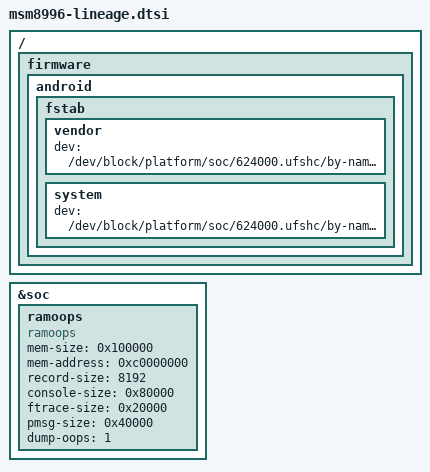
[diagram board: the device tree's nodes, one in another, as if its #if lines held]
/* Copyright (c) 2018 The LineageOS Project. All rights reserved.
 *
 * This program is free software; you can redistribute it and/or modify
 * it under the terms of the GNU General Public License version 2 and
 * only version 2 as published by the Free Software Foundation.
 *
 * This program is distributed in the hope that it will be useful,
 * but WITHOUT ANY WARRANTY; without even the implied warranty of
 * MERCHANTABILITY or FITNESS FOR A PARTICULAR PURPOSE.  See the
 * GNU General Public License for more details.
 */

/ {
	firmware: firmware {
		android {
			fstab {
#ifdef CONFIG_LGE_MSM8996_ENABLE_VENDOR
				vendor {
                                        dev = "/dev/block/platform/soc/624000.ufshc/by-name/vendor";
                                };
#else
				/delete-node/ vendor;
#endif
				system {
					dev = "/dev/block/platform/soc/624000.ufshc/by-name/system";
				};
			};
		};
	};
};

&soc {
#ifdef CONFIG_LGE_KERNEL44_RAMOOPS
	/* Make kernel better able to get
	 * ramoops dumped by 4.4 kernel.
	 */
	ramoops {
		compatible = "ramoops";
		mem-size = <0x100000>;
		mem-address = <0xc0000000>;
		record-size = <8192>;
		console-size = <0x80000>;
		ftrace-size = <0x20000>;
		pmsg-size = <0x40000>;
		dump-oops = <1>;
	};
#else
	/*  Original */
	ramoops {
		compatible = "ramoops";
#ifdef CONFIG_MACH_MSM8996_LUCYE
		mem-size = <0xc0000>;
#else
		mem-size = <0x80000>;
#endif
		mem-address = <0xc0000000>;
		record-size = <4096>;
		console-size = <0x40000>;
		ftrace-size = <0x40000>;
#ifdef CONFIG_MACH_MSM8996_LUCYE
		pmsg-size = <0x40000>;
#endif
		dump-oops = <1>;
	};
#endif /* CONFIG_LGE_KERNEL44_RAMOOPS */
};
